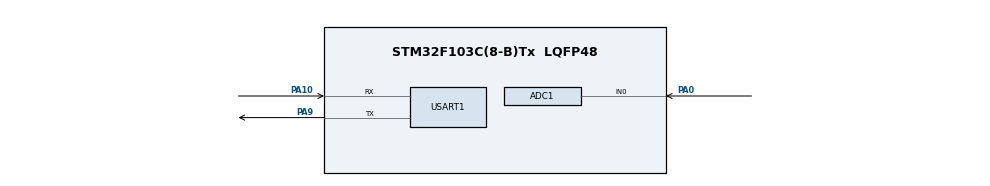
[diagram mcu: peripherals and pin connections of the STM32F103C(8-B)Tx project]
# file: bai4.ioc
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ADC1.Channel-0\#ChannelRegularConversion=ADC_CHANNEL_0
ADC1.ExternalTrigConv=ADC_EXTERNALTRIGCONV_T2_CC2
ADC1.NbrOfConversionFlag=1
ADC1.Rank-0\#ChannelRegularConversion=1
ADC1.SamplingTime-0\#ChannelRegularConversion=ADC_SAMPLETIME_1CYCLE_5
ADC1.master=1
Dma.ADC1.0.Direction=DMA_PERIPH_TO_MEMORY
Dma.ADC1.0.Instance=DMA1_Channel1
Dma.ADC1.0.MemDataAlignment=DMA_MDATAALIGN_HALFWORD
Dma.ADC1.0.MemInc=DMA_MINC_ENABLE
Dma.ADC1.0.Mode=DMA_CIRCULAR
Dma.ADC1.0.PeriphDataAlignment=DMA_PDATAALIGN_HALFWORD
Dma.ADC1.0.PeriphInc=DMA_PINC_DISABLE
Dma.ADC1.0.Priority=DMA_PRIORITY_LOW
Dma.Request0=ADC1
Mcu.Family=STM32F1
Mcu.Name=STM32F103C(8-B)Tx
Mcu.Package=LQFP48
NVIC.DMA1_Channel1_IRQn=true\:0\:0\:false\:false\:true\:false\:true\:true
NVIC.PriorityGroup=NVIC_PRIORITYGROUP_4
PA0-WKUP.Signal=ADCx_IN0
PA10.Mode=Asynchronous
PA10.Signal=USART1_RX
PA13.Mode=Serial_Wire
PA13.Signal=SYS_JTMS-SWDIO
PA14.Mode=Serial_Wire
PA14.Signal=SYS_JTCK-SWCLK
PA9.Mode=Asynchronous
PA9.Signal=USART1_TX
PD0-OSC_IN.Mode=HSE-External-Oscillator
PD0-OSC_IN.Signal=RCC_OSC_IN
PD1-OSC_OUT.Mode=HSE-External-Oscillator
PD1-OSC_OUT.Signal=RCC_OSC_OUT
ProjectManager.HeapSize=0x200
ProjectManager.StackSize=0x400
ProjectManager.TargetToolchain=STM32CubeIDE
RCC.APB1Freq_Value=8000000
RCC.APB2Freq_Value=8000000
SH.ADCx_IN0.0=ADC1_IN0,IN0
TIM2.Period=999
TIM2.Prescaler=719
TIM2.TIM_MasterOutputTrigger=TIM_TRGO_UPDATE
USART1.VirtualMode=VM_ASYNC
VP_TIM2_VS_ClockSourceINT.Mode=Internal
board=custom

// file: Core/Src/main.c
/* USER CODE BEGIN Header */
/**
  ******************************************************************************
  * @file           : main.c
  * @brief          : Main program body
  ******************************************************************************
  * @attention
  *
  * Copyright (c) 2026 STMicroelectronics.
  * All rights reserved.
  *
  * This software is licensed under terms that can be found in the LICENSE file
  * in the root directory of this software component.
  * If no LICENSE file comes with this software, it is provided AS-IS.
  *
  ******************************************************************************
  */
/* USER CODE END Header */
#include "main.h"

/* USER CODE BEGIN Includes */
#include <stdio.h>
#include <string.h>
/* USER CODE END Includes */

/* USER CODE BEGIN PTD */
typedef enum {
  BUFFER_IDLE = 0,
  BUFFER_FIRST_HALF_READY,
  BUFFER_SECOND_HALF_READY
} BufferState_t;
/* USER CODE END PTD */

/* USER CODE BEGIN PD */
#define TOTAL_SAMPLES       100                       // 100 Hz trong 1 giay = 100 mau
#define HALF_SAMPLES        (TOTAL_SAMPLES / 2)       // 50 mau moi lan ngat
/* USER CODE END PD */

ADC_HandleTypeDef hadc1;
DMA_HandleTypeDef hdma_adc1;

TIM_HandleTypeDef htim2;

UART_HandleTypeDef huart1;

/* USER CODE BEGIN PV */
uint16_t adc_buffer[TOTAL_SAMPLES];
volatile BufferState_t buffer_state = BUFFER_IDLE;
char tx_buffer[32];
/* USER CODE END PV */

void SystemClock_Config(void);
static void MX_GPIO_Init(void);
static void MX_DMA_Init(void);
static void MX_ADC1_Init(void);
static void MX_TIM2_Init(void);
static void MX_USART1_UART_Init(void);
/* USER CODE BEGIN PFP */
static void Send_ADC_Data_UART(uint16_t *pData, uint16_t length);
/* USER CODE END PFP */

/* USER CODE BEGIN 0 */
// Callback khi DMA ghi day 50% buffer dau (Mau 0 -> 49)
void HAL_ADC_ConvHalfCpltCallback(ADC_HandleTypeDef* hadc)
{
  if (hadc->Instance == ADC1)
  {
    buffer_state = BUFFER_FIRST_HALF_READY;
  }
}

// Callback khi DMA ghi day 50% buffer sau (Mau 50 -> 99)
void HAL_ADC_ConvCpltCallback(ADC_HandleTypeDef* hadc)
{
  if (hadc->Instance == ADC1)
  {
    buffer_state = BUFFER_SECOND_HALF_READY;
  }
}

// Ham truyen tung mau so len PC qua UART ngat nhau boi \r\n
static void Send_ADC_Data_UART(uint16_t *pData, uint16_t length)
{
  for (uint16_t i = 0; i < length; i++)
  {
    int len = snprintf(tx_buffer, sizeof(tx_buffer), "%u\r\n", pData[i]);
    if (len > 0)
    {
      HAL_UART_Transmit(&huart1, (uint8_t*)tx_buffer, (uint16_t)len, HAL_MAX_DELAY);
    }
  }
}
/* USER CODE END 0 */

int main(void)
{

  /* MCU Configuration--------------------------------------------------------*/

  /* Reset of all peripherals, Initializes the Flash interface and the Systick. */
  HAL_Init();

  /* Configure the system clock */
  SystemClock_Config();

  /* Initialize all configured peripherals */
  MX_GPIO_Init();
  MX_DMA_Init();
  MX_ADC1_Init();
  MX_TIM2_Init();
  MX_USART1_UART_Init();
  /* USER CODE BEGIN 2 */
  // 1. Can chinh ADC truoc khi bat dau
  HAL_ADCEx_Calibration_Start(&hadc1);

  // 2. Khoi dong ADC o che do DMA Circular (100 mau)
  HAL_ADC_Start_DMA(&hadc1, (uint32_t*)adc_buffer, TOTAL_SAMPLES);

  // 3. Khoi dong TIM2 Base va Channel 2 de phat xung trigger 100Hz cho ADC
  HAL_TIM_Base_Start(&htim2);
  HAL_TIM_OC_Start(&htim2, TIM_CHANNEL_2);
  /* USER CODE END 2 */

  /* Infinite loop */
  while (1)
  {

    /* USER CODE BEGIN 3 */
    if (buffer_state == BUFFER_FIRST_HALF_READY)
    {
      // Truyen nua dau (0 -> 49) len PC an toan trong khi DMA dang ghi nua sau
      Send_ADC_Data_UART(&adc_buffer[0], HALF_SAMPLES);
      buffer_state = BUFFER_IDLE;
    }
    else if (buffer_state == BUFFER_SECOND_HALF_READY)
    {
      // Truyen nua sau (50 -> 99) len PC an toan trong khi DMA quay vong ghi vao nua dau
      Send_ADC_Data_UART(&adc_buffer[HALF_SAMPLES], HALF_SAMPLES);
      buffer_state = BUFFER_IDLE;
    }
  }
  /* USER CODE END 3 */
}

void SystemClock_Config(void)
{
  RCC_OscInitTypeDef RCC_OscInitStruct = {0};
  RCC_ClkInitTypeDef RCC_ClkInitStruct = {0};
  RCC_PeriphCLKInitTypeDef PeriphClkInit = {0};

  /** Initializes the RCC Oscillators according to the specified parameters
  * in the RCC_OscInitTypeDef structure.
  */
  RCC_OscInitStruct.OscillatorType = RCC_OSCILLATORTYPE_HSI;
  RCC_OscInitStruct.HSIState = RCC_HSI_ON;
  RCC_OscInitStruct.HSICalibrationValue = RCC_HSICALIBRATION_DEFAULT;
  RCC_OscInitStruct.PLL.PLLState = RCC_PLL_NONE;
  if (HAL_RCC_OscConfig(&RCC_OscInitStruct) != HAL_OK)
  {
    Error_Handler();
  }

  /** Initializes the CPU, AHB and APB buses clocks
  */
  RCC_ClkInitStruct.ClockType = RCC_CLOCKTYPE_HCLK|RCC_CLOCKTYPE_SYSCLK
                              |RCC_CLOCKTYPE_PCLK1|RCC_CLOCKTYPE_PCLK2;
  RCC_ClkInitStruct.SYSCLKSource = RCC_SYSCLKSOURCE_HSI;
  RCC_ClkInitStruct.AHBCLKDivider = RCC_SYSCLK_DIV1;
  RCC_ClkInitStruct.APB1CLKDivider = RCC_HCLK_DIV1;
  RCC_ClkInitStruct.APB2CLKDivider = RCC_HCLK_DIV1;

  if (HAL_RCC_ClockConfig(&RCC_ClkInitStruct, FLASH_LATENCY_0) != HAL_OK)
  {
    Error_Handler();
  }
  PeriphClkInit.PeriphClockSelection = RCC_PERIPHCLK_ADC;
  PeriphClkInit.AdcClockSelection = RCC_ADCPCLK2_DIV2;
  if (HAL_RCCEx_PeriphCLKConfig(&PeriphClkInit) != HAL_OK)
  {
    Error_Handler();
  }
}

static void MX_ADC1_Init(void)
{

  ADC_ChannelConfTypeDef sConfig = {0};

  /** Common config
  */
  hadc1.Instance = ADC1;
  hadc1.Init.ScanConvMode = ADC_SCAN_DISABLE;
  hadc1.Init.ContinuousConvMode = DISABLE;
  hadc1.Init.DiscontinuousConvMode = DISABLE;
  // Trigger phan cung tu Timer 2 Channel 2 (chuan F103)
  hadc1.Init.ExternalTrigConv = ADC_EXTERNALTRIGCONV_T2_CC2;
  hadc1.Init.DataAlign = ADC_DATAALIGN_RIGHT;
  hadc1.Init.NbrOfConversion = 1;
  if (HAL_ADC_Init(&hadc1) != HAL_OK)
  {
    Error_Handler();
  }

  /** Configure Regular Channel
  */
  sConfig.Channel = ADC_CHANNEL_0;
  sConfig.Rank = ADC_REGULAR_RANK_1;
  sConfig.SamplingTime = ADC_SAMPLETIME_1CYCLE_5;
  if (HAL_ADC_ConfigChannel(&hadc1, &sConfig) != HAL_OK)
  {
    Error_Handler();
  }

}

static void MX_TIM2_Init(void)
{

  TIM_ClockConfigTypeDef sClockSourceConfig = {0};
  TIM_MasterConfigTypeDef sMasterConfig = {0};
  TIM_OC_InitTypeDef sConfigOC = {0};

  htim2.Instance = TIM2;
  // Xung clock noi HSI = 8 MHz, Prescaler = 79, Period = 999 -> Tần số = 8.000.000 / (80 * 1000) = 100 Hz
  htim2.Init.Prescaler = 79;
  htim2.Init.CounterMode = TIM_COUNTERMODE_UP;
  htim2.Init.Period = 999;
  htim2.Init.ClockDivision = TIM_CLOCKDIVISION_DIV1;
  htim2.Init.AutoReloadPreload = TIM_AUTORELOAD_PRELOAD_DISABLE;
  if (HAL_TIM_Base_Init(&htim2) != HAL_OK)
  {
    Error_Handler();
  }
  sClockSourceConfig.ClockSource = TIM_CLOCKSOURCE_INTERNAL;
  if (HAL_TIM_ConfigClockSource(&htim2, &sClockSourceConfig) != HAL_OK)
  {
    Error_Handler();
  }
  if (HAL_TIM_OC_Init(&htim2) != HAL_OK)
  {
    Error_Handler();
  }
  sMasterConfig.MasterOutputTrigger = TIM_TRGO_RESET;
  sMasterConfig.MasterSlaveMode = TIM_MASTERSLAVEMODE_DISABLE;
  if (HAL_TIMEx_MasterConfigSynchronization(&htim2, &sMasterConfig) != HAL_OK)
  {
    Error_Handler();
  }

  // Cau hinh Output Compare Channel 2 tao canh kich hoat ADC
  sConfigOC.OCMode = TIM_OCMODE_TOGGLE;
  sConfigOC.Pulse = 500;
  sConfigOC.OCPolarity = TIM_OCPOLARITY_HIGH;
  sConfigOC.OCFastMode = TIM_OCFAST_DISABLE;
  if (HAL_TIM_OC_ConfigChannel(&htim2, &sConfigOC, TIM_CHANNEL_2) != HAL_OK)
  {
    Error_Handler();
  }

}

static void MX_USART1_UART_Init(void)
{

  huart1.Instance = USART1;
  huart1.Init.BaudRate = 115200;
  huart1.Init.WordLength = UART_WORDLENGTH_8B;
  huart1.Init.StopBits = UART_STOPBITS_1;
  huart1.Init.Parity = UART_PARITY_NONE;
  huart1.Init.Mode = UART_MODE_TX_RX;
  huart1.Init.HwFlowCtl = UART_HWCONTROL_NONE;
  huart1.Init.OverSampling = UART_OVERSAMPLING_16;
  if (HAL_UART_Init(&huart1) != HAL_OK)
  {
    Error_Handler();
  }

}

static void MX_DMA_Init(void)
{

  /* DMA controller clock enable */
  __HAL_RCC_DMA1_CLK_ENABLE();

  /* DMA interrupt init */
  /* DMA1_Channel1_IRQn interrupt configuration */
  HAL_NVIC_SetPriority(DMA1_Channel1_IRQn, 0, 0);
  HAL_NVIC_EnableIRQ(DMA1_Channel1_IRQn);

}

static void MX_GPIO_Init(void)
{

  /* GPIO Ports Clock Enable */
  __HAL_RCC_GPIOD_CLK_ENABLE();
  __HAL_RCC_GPIOA_CLK_ENABLE();

}

void Error_Handler(void)
{
  __disable_irq();
  while (1)
  {
  }
}
